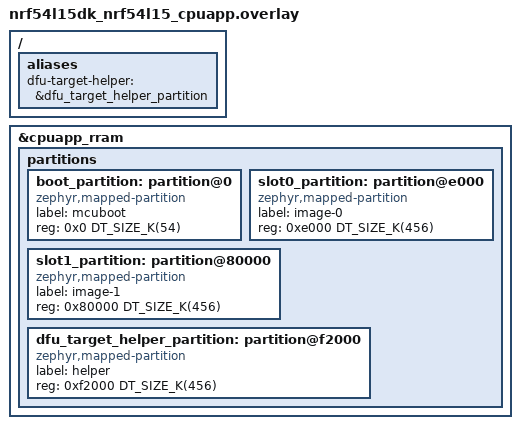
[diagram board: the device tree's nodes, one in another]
/*
 * Copyright (c) 2026 Nordic Semiconductor ASA
 *
 * SPDX-License-Identifier: LicenseRef-Nordic-5-Clause
 */

/delete-node/ &boot_partition;
/delete-node/ &slot0_partition;
/delete-node/ &slot1_partition;
/delete-node/ &storage_partition;

&cpuapp_rram {
	partitions {
		boot_partition: partition@0 {
			compatible = "zephyr,mapped-partition";
			label = "mcuboot";
			reg = <0x0 DT_SIZE_K(54)>;
		};

		slot0_partition: partition@e000 {
			compatible = "zephyr,mapped-partition";
			label = "image-0";
			reg = <0xe000 DT_SIZE_K(456)>;
		};

		slot1_partition: partition@80000 {
			compatible = "zephyr,mapped-partition";
			label = "image-1";
			reg = <0x80000 DT_SIZE_K(456)>;
		};

		dfu_target_helper_partition: partition@f2000 {
			compatible = "zephyr,mapped-partition";
			label = "helper";
			reg = <0xf2000 DT_SIZE_K(456)>;
		};
	};
};

/ {
	aliases {
		dfu-target-helper = &dfu_target_helper_partition;
	};
};
